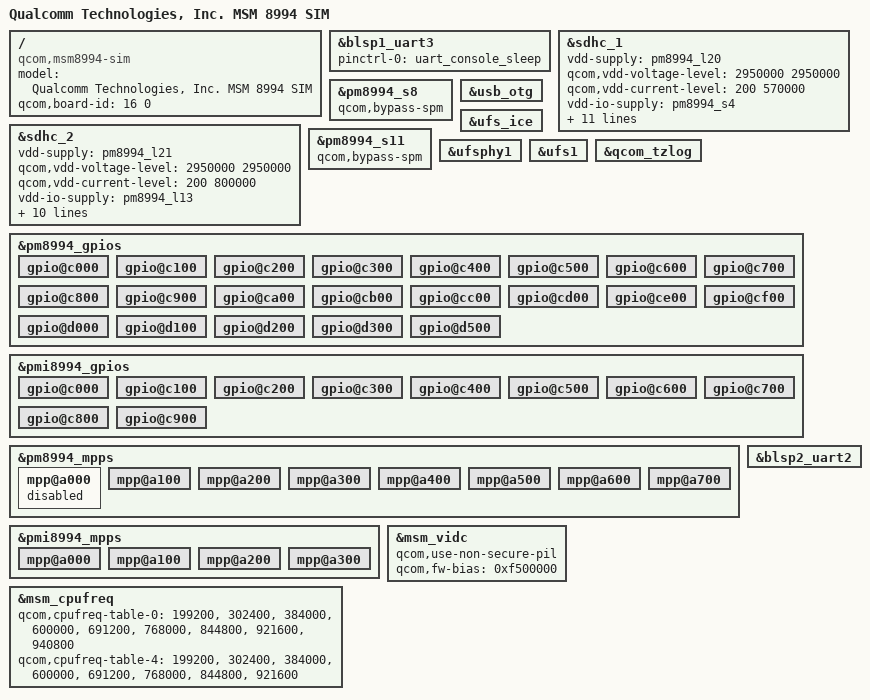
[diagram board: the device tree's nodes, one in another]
/* Copyright (c) 2013-2014, The Linux Foundation. All rights reserved.
 *
 * This program is free software; you can redistribute it and/or modify
 * it under the terms of the GNU General Public License version 2 and
 * only version 2 as published by the Free Software Foundation.
 *
 * This program is distributed in the hope that it will be useful,
 * but WITHOUT ANY WARRANTY; without even the implied warranty of
 * MERCHANTABILITY or FITNESS FOR A PARTICULAR PURPOSE.  See the
 * GNU General Public License for more details.
 */


/dts-v1/;

/memreserve/ 0x06000000 0x00001000;

#include "msm8994-v1.dtsi"
#include "msm8994-pinctrl.dtsi"
#include "msm8994-bus.dtsi"
/ {
	model = "Qualcomm Technologies, Inc. MSM 8994 SIM";
	compatible = "qcom,msm8994-sim", "qcom,msm8994", "qcom,sim";
	qcom,board-id = <16 0>;
};

&blsp1_uart3 {
	status = "ok";
	pinctrl-names = "default";
	pinctrl-0 = <&uart_console_sleep>;
};

&sdhc_1 {
	vdd-supply = <&pm8994_l20>;
	qcom,vdd-voltage-level = <2950000 2950000>;
	qcom,vdd-current-level = <200 570000>;

	vdd-io-supply = <&pm8994_s4>;
	qcom,vdd-io-always-on;
	qcom,vdd-io-voltage-level = <1800000 1800000>;
	qcom,vdd-io-current-level = <200 325000>;

	pinctrl-names = "active", "sleep";
	pinctrl-0 = <&sdc1_clk_on &sdc1_cmd_on &sdc1_data_on &sdc1_rclk_on>;
	pinctrl-1 = <&sdc1_clk_off &sdc1_cmd_off &sdc1_data_off &sdc1_rclk_off>;

	qcom,clk-rates = <400000 20000000 25000000 50000000 100000000 200000000>;
	qcom,nonremovable;
	qcom,bus-speed-mode = "HS200_1p8v", "DDR_1p8v";
	status = "ok";
};

&sdhc_2 {
	vdd-supply = <&pm8994_l21>;
	qcom,vdd-voltage-level = <2950000 2950000>;
	qcom,vdd-current-level = <200 800000>;

	vdd-io-supply = <&pm8994_l13>;
	qcom,vdd-io-voltage-level = <1800000 2950000>;
	qcom,vdd-io-current-level = <200 22000>;

	pinctrl-names = "active", "sleep";
	pinctrl-0 = <&sdc2_clk_on &sdc2_cmd_on &sdc2_data_on>;
	pinctrl-1 = <&sdc2_clk_off &sdc2_cmd_off &sdc2_data_off>;

	qcom,clk-rates = <400000 20000000 25000000 50000000 100000000 200000000>;
	qcom,bus-speed-mode = "SDR12", "SDR25", "SDR50", "DDR50", "SDR104";
	status = "ok";
};

&pm8994_s8 {
	qcom,bypass-spm;
};

&pm8994_s11 {
	qcom,bypass-spm;
};

&usb_otg {
	status = "ok";
};

&ufs_ice {
	status = "ok";
};

&ufsphy1 {
	status = "ok";
};

&ufs1 {
	status = "ok";
};

&qcom_tzlog {
	status = "okay";
};

&pm8994_gpios {
	gpio@c000 { /* GPIO 1 */
	};

	gpio@c100 { /* GPIO 2 */
	};

	gpio@c200 { /* GPIO 3 */
	};

	gpio@c300 { /* GPIO 4 */
	};

	gpio@c400 { /* GPIO 5 */
	};

	gpio@c500 { /* GPIO 6 */
	};

	gpio@c600 { /* GPIO 7 */
	};

	gpio@c700 { /* GPIO 8 */
	};

	gpio@c800 { /* GPIO 9 */
	};

	gpio@c900 { /* GPIO 10 */
	};

	gpio@ca00 { /* GPIO 11 */
	};

	gpio@cb00 { /* GPIO 12 */
	};

	gpio@cc00 { /* GPIO 13 */
	};

	gpio@cd00 { /* GPIO 14 */
	};

	gpio@ce00 { /* GPIO 15 */
	};

	gpio@cf00 { /* GPIO 16 */
	};

	gpio@d000 { /* GPIO 17 */
	};

	gpio@d100 { /* GPIO 18 */
	};

	gpio@d200 { /* GPIO 19 */
	};

	gpio@d300 { /* GPIO 20 */
	};

	gpio@d500 { /* GPIO 22 */
	};
};

&pmi8994_gpios {
	gpio@c000 { /* GPIO 1 */
	};

	gpio@c100 { /* GPIO 2 */
	};

	gpio@c200 { /* GPIO 3 */
	};

	gpio@c300 { /* GPIO 4 */
	};

	gpio@c400 { /* GPIO 5 */
	};

	gpio@c500 { /* GPIO 6 */
	};

	gpio@c600 { /* GPIO 7 */
	};

	gpio@c700 { /* GPIO 8 */
	};

	gpio@c800 { /* GPIO 9 */
	};

	gpio@c900 { /* GPIO 10 */
	};
};

&pm8994_mpps {
	mpp@a000 { /* MPP 1 */
		status = "disabled";
	};

	mpp@a100 { /* MPP 2 */
	};

	mpp@a200 { /* MPP 3 */
	};

	mpp@a300 { /* MPP 4 */
	};

	mpp@a400 { /* MPP 5 */
	};

	mpp@a500 { /* MPP 6 */
	};

	mpp@a600 { /* MPP 7 */
	};

	mpp@a700 { /* MPP 8 */
	};
};

&pmi8994_mpps {
	mpp@a000 { /* MPP 1 */
	};

	mpp@a100 { /* MPP 2 */
	};

	mpp@a200 { /* MPP 3 */
	};

	mpp@a300 { /* MPP 4 */
	};
};

&msm_vidc {
	qcom,use-non-secure-pil;
	qcom,fw-bias = <0xf500000>;
};

&blsp2_uart2 {
	status = "ok";
};

&msm_cpufreq {
	qcom,cpufreq-table-0 =
		<  199200 >,
		<  302400 >,
		<  384000 >,
		<  600000 >,
		<  691200 >,
		<  768000 >,
		<  844800 >,
		<  921600 >,
		<  940800 >;

	qcom,cpufreq-table-4 =
		<  199200 >,
		<  302400 >,
		<  384000 >,
		<  600000 >,
		<  691200 >,
		<  768000 >,
		<  844800 >,
		<  921600 >;
};
